# cpsw_CPSW3_08000000h register map
Vendor: Texas Instruments
Registers are 32-bit, read-write, reset 0x0 unless marked. A register's access mark holds for its fields unless they carry their own. Offsets are as the file gives them; [hi:lo] are bit positions; {n}, {i} and the like mark numbered series; 'fields as' and 'values as' point back to an identical list.

## cpsw3 (part 2 of 3)
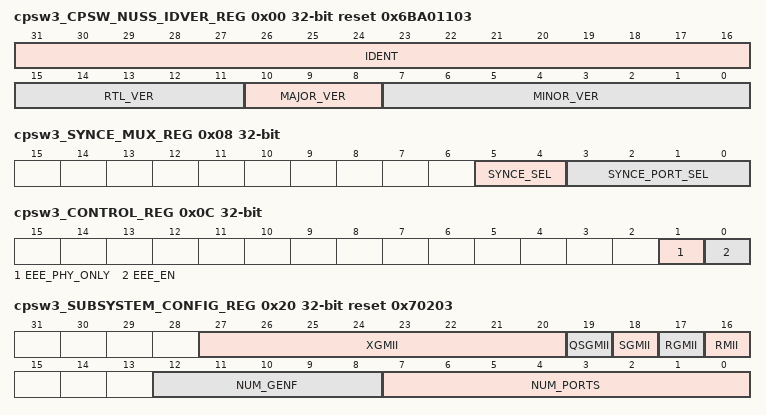
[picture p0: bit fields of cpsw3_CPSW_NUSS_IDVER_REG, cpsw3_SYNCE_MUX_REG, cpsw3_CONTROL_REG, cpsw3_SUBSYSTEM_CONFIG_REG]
0x00 cpsw3_CPSW_NUSS_IDVER_REG ro reset 0x6BA01103 — ID Version Register
  [31:16] IDENT — Identification value
  [15:11] RTL_VER — RTL version value
  [10:8] MAJOR_VER — Major version value
  [7:0] MINOR_VER — Minor version value
0x04 cpsw3_SYNCE_COUNT_REG — SyncE Count Register
  [31:0] SYNCE_CNT — Sync E Count Value
0x08 cpsw3_SYNCE_MUX_REG — SyncE Mux Register
  [5:4] SYNCE_SEL — Sync E Interface Select. 0h GMIIn_MRCLK_I input clock from selected port.1h RMII_MHZ_50_CLK (same for all ports).2h RGMIIn_RXC_I input clock from selected port.3h SERDESn_RXCLK from selected port.
  [3:0] SYNCE_PORT_SEL — Sync E Port SelectThis field selects the port that will be used for Synchronous Ethernet receive clock. The port interface is selected with synce_sel. 0h Port 1.1h Port 2.2h-Fh Reserved.
0x0C cpsw3_CONTROL_REG — Control Register
  [1] EEE_PHY_ONLY — Energy Efficient Enable Phy Only Mode: 0h The low power indicate state includes gating off the CPPI_GCLK to the CPSW.1h The low power indicate state does not gate the clock to the CPSW.
  [0] EEE_EN — Energy Efficient Ethernet Enable: 0h EEE is disabled1h EEE is enabled
0x10 cpsw3_SGMII_NON_FIBER_MODE_REG reset 0x3 — SGMII NON FIBER Mode Register
  [1:0] SGMII_NON_FIBER_MODE — This register bit goes to the CPSGMII mode input only
0x14 cpsw3_SERDES_RESET_ISO_REG — SyncE Mux Register
  [1:0] SERDES_RESET_ISO — These bits control whether the SERDES ignores the hard reset for isolation or not
0x1C cpsw3_SUBSSYSTEM_STATUS_REG ro — Subsystem Status Register
  [0] EEE_CLKSTOP_ACK — Energy Efficient Ethernet clockstop acknowledge from CPSW
0x20 cpsw3_SUBSYSTEM_CONFIG_REG ro reset 0x70203 — Subsystem Configuration Register
  [27:20] XGMII — The Number of XGMII Ports included in the CPSW_NUSS
  [19] QSGMII — QSGMII is included in the CPSW_NUSS
  [18] SGMII — SGMII is included in the CPSW_NUSS
  [17] RGMII — RGMII is included in the CPSW_NUSS
  [16] RMII — RMII is included in the CPSW_NUSS
  [12:8] NUM_GENF — The number of CPTS GENF outputs
  [7:0] NUM_PORTS — The total number of ports including the host port 0
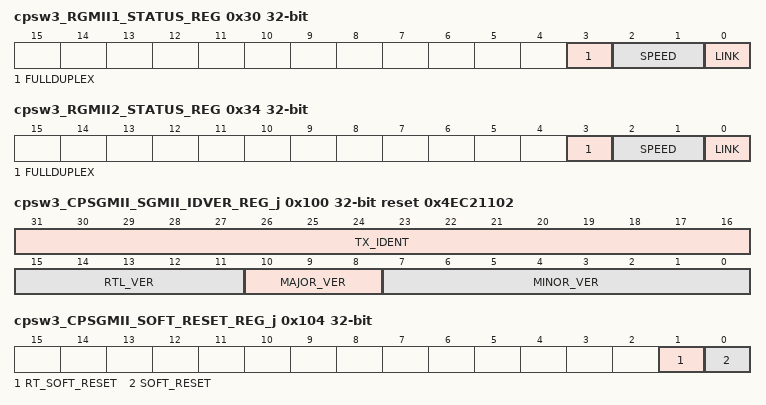
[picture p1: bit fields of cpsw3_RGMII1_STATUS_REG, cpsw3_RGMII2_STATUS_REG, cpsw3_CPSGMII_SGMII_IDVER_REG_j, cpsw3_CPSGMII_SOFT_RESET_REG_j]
0x30 cpsw3_RGMII1_STATUS_REG ro — RGMII1 Status Register
  [3] FULLDUPLEX — RGMII Port 1 full duplex: 0h Half-duplex1h Full-duplex
  [2:1] SPEED — RGMII Port 1 speed: 0h 10Mbps1h 100Mbps2h 1000Mbps3h Reserved
  [0] LINK — RGMII Port 1 link indicator: 0h Link is down,1h Link is up
0x34 cpsw3_RGMII2_STATUS_REG ro — RGMII2 Status Register
  [3] FULLDUPLEX — RGMII Port 2 full dulex: 0h Half-duplex1h Full-duplex
  [2:1] SPEED — RGMII Port 2 speed: 0h 10Mbps1h 100Mbps2h 1000Mbps3h Reserved
  [0] LINK — RGMII Port 2 link indicator: 0h Link is down1h Link is up
0x100 cpsw3_CPSGMII_SGMII_IDVER_REG_j ro reset 0x4EC21102 — SGMII IDVER register
  [31:16] TX_IDENT — MODULE value
  [15:11] RTL_VER — RTL version value
  [10:8] MAJOR_VER — Major version value
  [7:0] MINOR_VER — Minor version value
0x104 cpsw3_CPSGMII_SOFT_RESET_REG_j — SGMII Soft Reset Register
  [1] RT_SOFT_RESET — Transmit and receive software reset
  [0] SOFT_RESET — Software reset
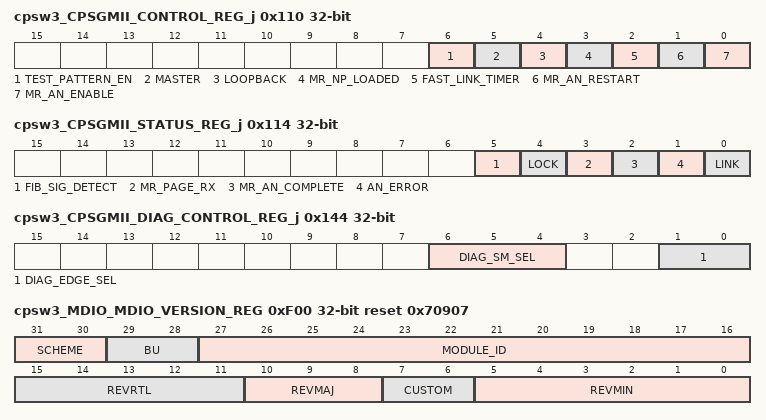
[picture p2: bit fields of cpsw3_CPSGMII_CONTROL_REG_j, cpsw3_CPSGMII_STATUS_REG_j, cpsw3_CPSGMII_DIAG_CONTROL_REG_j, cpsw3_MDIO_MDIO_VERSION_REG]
0x110 cpsw3_CPSGMII_CONTROL_REG_j — SGMII Control Register
  [6] TEST_PATTERN_EN — Test pattern enable
  [5] MASTER — Master mode
  [4] LOOPBACK — Loopback mode
  [3] MR_NP_LOADED — Next page loaded
  [2] FAST_LINK_TIMER
  [1] MR_AN_RESTART — Auto-negotiation restart
  [0] MR_AN_ENABLE — Auto-negotiation enable
0x114 cpsw3_CPSGMII_STATUS_REG_j ro — SGMII Status Register
  [5] FIB_SIG_DETECT — Fiber signal detect
  [4] LOCK
  [3] MR_PAGE_RX — Next page received
  [2] MR_AN_COMPLETE — Auto-negotiation complete
  [1] AN_ERROR — Auto-negotiation error
  [0] LINK — Link indicator
0x118 cpsw3_CPSGMII_MR_ADV_ABILITY_REG_j — SGMII MR Advertized Ability Register
  [15:0] MR_ADV_ABILITY — Advertised ability
0x11C cpsw3_CPSGMII_MR_NP_TX_REG_j — SGMII Next Pate Transmit Register
  [15:0] MR_NP_TX — Next page transmit
0x120 cpsw3_CPSGMII_MR_LP_ADV_ABILITY_REG_j ro — SGMII Link Partner Advertized Ability Register
  [15:0] MR_LP_ADV_ABILITY — Link partner advertised ability
0x124 cpsw3_CPSGMII_MR_LP_NP_RX_REG_j ro — SGMII Link Partner Next Page Receive Register
  [15:0] MR_LP_NP_RX — Link Partner Next Page Received
0x140 cpsw3_CPSGMII_DIAG_CLEAR_REG_j — SGMII Diagnostics Clear Register
  [0] DIAG_CLEAR — Diagnostics clear
0x144 cpsw3_CPSGMII_DIAG_CONTROL_REG_j — SGMII Diagnostics Control Register
  [6:4] DIAG_SM_SEL — Diagnostic select
  [1:0] DIAG_EDGE_SEL — Diagnostics hold signals edge select
0x148 cpsw3_CPSGMII_DIAG_STATUS_REG_j ro — SGMII Diagnostics Status Register
  [15:0] DIAG_STATUS — Diagnostics status
0xF00 cpsw3_MDIO access not given reset not defined
0xF00 cpsw3_MDIO_MDIO_VERSION_REG ro reset 0x70907 — MDIO Version Register
  [31:30] SCHEME
  [29:28] BU
  [27:16] MODULE_ID
  [15:11] REVRTL — RTL version
  [10:8] REVMAJ — Major version
  [7:6] CUSTOM — Custom version
  [5:0] REVMIN — Minor version
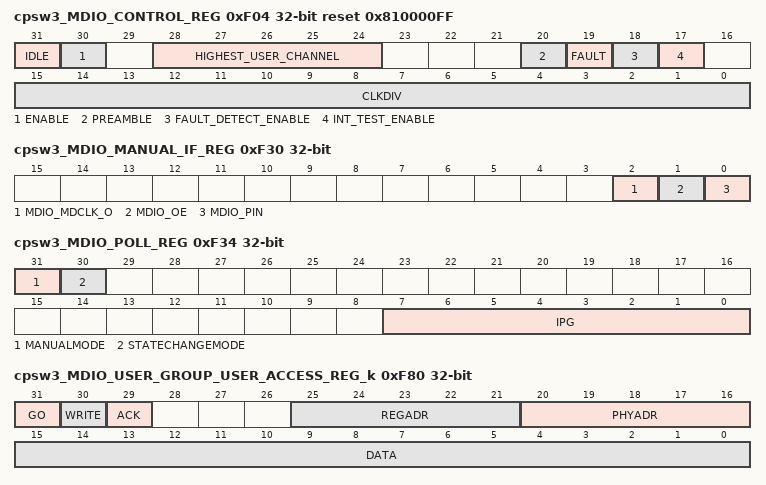
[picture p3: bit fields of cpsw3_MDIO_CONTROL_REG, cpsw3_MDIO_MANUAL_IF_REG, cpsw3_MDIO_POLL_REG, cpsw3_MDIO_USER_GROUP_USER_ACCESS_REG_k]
0xF04 cpsw3_MDIO_CONTROL_REG access per field reset 0x810000FF — MDIO Control Register
  [31] IDLE ro — MDIO state machine IDLE. Set to 1h when the state machine is in the idle state.
  [30] ENABLE rw — Enable control. Writing a 1h to this bit enables the MDIO state machine, writing a 0h disables it. If the MDIO state machine is active at the time it is disabled, it will complete the current operation before halting and setting the idle bit. If using byte access, the enable bit has to be the last bit written in this register.
  [28:24] HIGHEST_USER_CHANNEL ro — Highest user channel. This field specifies the highest useraccess channel that is available in the module and is currently set to 1h. This implies that MDIOUserAccess1 is the highest available user access channel.
  [20] PREAMBLE rw — Preamble disable. Writing a 1h to this bit disables this device from sending MDIO frame preambles in clause 22 mode of operation. This bit has no effect in clause 45 mode of operation.
  [19] FAULT rw — Fault indicator. This bit is set to 1h if the MDIO pins fail to read back what the device is driving onto them. This indicates a physical layer fault and the module state machine is reset. Writing a 1h to it clears this bit.
  [18] FAULT_DETECT_ENABLE rw — Fault detect enable. This bit has to be set to 1h to enable the physical layer fault detection.
  [17] INT_TEST_ENABLE rw — Interrupt test enable. This bit can be set to 1h to enable the host to set the userint and linkint bits for test purposes.
  [15:0] CLKDIV rw — Clock Divider. This field specifies the division ratio between CLK and the frequency of MDCLK. When clkdiv is set to 0h, MDCLK is disabled and output is driven to a high logic state. MDCLK frequency = clk frequency/(clkdiv+1).
0xF08 cpsw3_MDIO_ALIVE_REG — MDIO Alive Register
  [31:0] ALIVE — MDIO Alive. Each of the 32-bits of this register is set if the most recent access to the PHY with address corresponding to the register bit number was acknowledged by the PHY, the bit is reset if the PHY fails to acknowledge the access. Both the user and polling accesses to a PHY will cause the corresponding alive bit to be updated. The alive bits are intended to be used to give an indication of the presence or not of the PHY with the corresponding address. Writing a 1h to any bit will clear it, writing a 0h has no effect.
0xF0C cpsw3_MDIO_LINK_REG ro — MDIO Link Register
  [31:0] LINK — MDIO Link state. This register is updated after a read of the Generic Status Register of a PHY. The corresponding bit is set if the PHY with the corresponding address has link and the PHY acknowledges the read transaction. The bit is cleared to 0h if the PHY indicates it does not have link or fails to acknowledge the read transaction. Writes to the register have no effect. In addition, in Normal Mode Operation, the status of the two PHYs specified in the MDIOUserPhySel registers can be determined using the MLINK input pins. This is determined by the linksel bit in the MDIOUserPhySel register. In State Change Mode the MLINK input pins are unused.
0xF10 cpsw3_MDIO_LINK_INT_RAW_REG — MDIO Link Interrupt Raw Register
  [1:0] LINKINTRAW — MDIO link change event raw value. Normal mode operation: When asserted '1', a bit indicates that there was an MDIO link change event (i.e. change in the MDIOLink register) corresponding to the PHY address in the MDIOUserPhySel register. [0]LINKINTRAW and [1]LINKINTRAW correspond to MDIOUserPhySel0 and MDIOUserPhysel1, respectively. Writing a 1h will clear the event and writing 0h has no effect. If the [17] INT_TEST_ENABLE bit in the CPSW_MDIO_CONTROL_REG register is set, the host may set LINKINTRAW bits to a 1h which may be used for test purposes. MDIO link change event raw value. State Change Mode operation: The [0]LINKINTRAW bit will be asserted '1' when any bit (for any PHY) in the MDIOAlive or MDIOLink registers changes due to MDIO operations. The [1]LINKINTRAW bit is unused in State Change Mode. State Change Mode allows any state change in any PHY to issue an interrupt. If the [17] INT_TEST_ENABLE bit in the CPSW_MDIO_CONTROL_REG register is set, the host may set the [0]LINKINTRAW bit to a 1h which may be used for test purposes.
0xF14 cpsw3_MDIO_LINK_INT_MASKED_REG — MDIO Link Interrupt Masked Register
  [1:0] LINKINTMASKED — MDIO link change interrupt masked value. Normal mode operation: When asserted '1', a bit indicates that there was an MDIO link change event (i.e. change in the MDIOLink register) corresponding to the PHY address in the MDIOUserPhySel register and the corresponding CPSW_MDIO_USER_PHY_SEL_REG_k[6] LINKINT_ENABLE bit was set. CPSW_MDIO_LINK_INT_MASKED_REG[0] LINKINTMASKED and [1] LINKINTMASKED correspond to MDIOUserPhySel0 and MDIOUserPhysel1, respectively. Writing a 1h will clear the interrupt and writing 0h has no effect. These masked interrupt bits are the MDIO_LINKINT[1:0] pin values. MDIO link change interrupt masked value. State Change Mode operation: The [0] LINKINTMASKED bit will be asserted '1' when CPSW_MDIO_LINK_INT_RAW_REG[0] LINKINTRAW is asserted '1' and when the CPSW_MDIO_LINK_INT_MASK_SET_REG[0] LINKINTMASKSET bit is set to 1h. Writing a 1h will clear [0] LINKINTMASKED (and the MDIO_LINKINT[0] output) and writing 0h has no effect. The [1] LINKINTMASKED bit is not used in State Change Mode (MDIO_LINKINT[1] is therefore also unused in State Change Mode).
0xF18 cpsw3_MDIO_LINK_INT_MASK_SET_REG — MDIO Link Interrupt Mask Set Register
  [0] LINKINTMASKSET — MDIO link interrupt mask set. Normal Mode Operation: This register is not used in normal mode. In normal mode the MDIO_LINKINT[1:0] interrupts are enabled with the linkint_enable bit in the associated MDIOUserPhySel0/1 register. MDIO link interrupt mask set. State Change Mode Operation: Writing this bit to 1h will enable the MDIO link status change interrupt (MDIO_LINKINT[0]) to be asserted when [0] LINKINTRAW is asserted.
0xF1C cpsw3_MDIO_LINK_INT_MASK_CLEAR_REG — MDIO Link Interrupt Mask Clear Register
  [0] LINKINTMASKCLR — MDIO link interrupt mask clear. Normal Mode Operation: This register is not used in normal mode. In normal mode the MDIO_LINKINT[1:0] interrupts are enabled with the linkint_enable bit in the associated MDIOUserPhySel0/1 register. MDIO link interrupt mask clear. State Change Mode Operation: Writing this bit to 1h will disable the MDIO link status change interrupt (MDIO_LINKINT[0]) regardless of the [0] LINKINTRAW bit value.
0xF20 cpsw3_MDIO_USER_INT_RAW_REG — MDIO User Interrupt Raw Register
  [1:0] USERINTRAW — Raw value of MDIO user command complete event for MDIOUserAccess1 through MDIOUserAccess0, respectively. When asserted '1', a bit indicates that the previously scheduled PHY read or write command using that particular MDIOUserAccess register has completed. Writing a 1h will clear the event and writing 0h has no effect. If the [17] INT_TEST_ENABLE bit in the CPSW_MDIO_CONTROL_REG register is set, the host may set the userintraw bits to a 1h. This mode may be used for test purposes.
0xF24 cpsw3_MDIO_USER_INT_MASKED_REG — MDIO User Interrupt Masked Register
  [1:0] USERINTMASKED — Masked value of MDIO user command complete interrupt for MDIOUserAccess1 through MDIOUserAccess0, respectively. When asserted '1', a bit indicates that the previously scheduled PHY read or write command using that particular MDIOUserAccess register has completed and the corresponding userintmaskset bit is set to 1h. Writing a 1h will clear the interrupt and writing 0h has no effect. If the [17] INT_TEST_ENABLE bit in the CPSW_MDIO_CONTROL_REG register is set, the host may set the CPSW_MDIO_USER_INT_MASKED_REG[1-0] USERINTMASKED bits to a 1h. This mode may be used for test purposes.
0xF28 cpsw3_MDIO_USER_INT_MASK_SET_REG — MDIO User Interrupt Mask Set Register
  [1:0] USERINTMASKSET — MDIO user interrupt mask set for CPSW_MDIO_USER_INT_MASKED_REG[1-0] USERINTMASKED, respectively. Writing a bit to 1h will enable MDIO user command complete interrupts for that particular MDIOUserAccess register. MDIO user interrupt for a particular MDIOUserAccess register is disabled if the corresponding bit is 0h. Writing a 0h to this register has no effect.
0xF2C cpsw3_MDIO_USER_INT_MASK_CLEAR_REG — MDIO User Interrupt Mask Clear Register
  [1:0] USERINTMASKCLR — MDIO user command complete interrupt mask clear for CPSW_MDIO_USER_INT_MASKED_REG[1-0] USERINTMASKED, respectively. Writing a bit to 1h will disable further user command complete interrupts for that particular MDIOUserAccess register. Writing a 0h to this register has no effect.
0xF30 cpsw3_MDIO_MANUAL_IF_REG — MDIO Manual Interface Register
  [2] MDIO_MDCLK_O — MDIO Clock Output. This value is the MDCLK_O output value when the [31] MANUALMODE bit is set in the CPSW_MDIO_POLL_REG register.
  [1] MDIO_OE — MDIO Output Enable. This value is inverted and output on the MDIO_OE_N output when the [31] MANUALMODE bit is set in the CPSW_MDIO_POLL_REG register.
  [0] MDIO_PIN — MDIO Pin Value. This is the external MDIO data pin value when the [31] MANUALMODE bit is set in the CPSW_MDIO_POLL_REG register. That is, this value is driven on the MDIO_O (the MDIO serial data output) when MDIO_OE is asserted '1'. The read value for this bit comes from MDIO_I (the MDIO serial data input). If MDIO_OE is asserted '1' and MDIO_PIN is written with a 1h then MDIO_PIN should read a 1h if there are no external devices pulling the MDIO data line low.
0xF34 cpsw3_MDIO_POLL_REG — MDIO Poll Register
  [31] MANUALMODE — MDIO Manual Mode. When set 1h, the MDIO pins are directly controlled by software through the bits in the CPSW_MDIO_MANUAL_IF_REG register 1h Manual Mode.
  [30] STATECHANGEMODE — MDIO State Change Mode. When set, the MDIO is operating in State Change Mode. When clear, the MDIO is operating in normal mode. State change mode effects interrupt operations. 0h Normal Mode.1h State Change Mode.
  [7:0] IPG — Polling Inter Packet Gap Value. This value is the number of MDCLK_O clocks between each poll when polling is enabled.
0xF38 cpsw3_MDIO_POLL_EN_REG reset 0xFFFFFFFF — MDIO Poll Enable Register
  [31:0] POLL_EN — MDIO Poll Enable. When set, the bit indicates that the associated PHY will be included in polling operations. When clear, the associated PHY will not be polled. Each bit in this field is associated with a PHY. Bit zero is associated with PHY 0 and so on. Due to a limitation in the hardware, bit 31 must always be set (regardless of the value of the preamble disable bit ([20] PREAMBLE) in the CPSW_MDIO_CONTROL_REG register. However, there does not have to be a PHY at address 31.
0xF3C cpsw3_MDIO_CLAUS45_REG — MDIO Clause45 Register
  [31:0] CLAUSE45 — MDIO clause 45 mode. When a clause45 bit is cleared 0h, the PHY associated with the clause45 bit is operating in the clause 22 mode. When set 1h, the PHY associated with the clause45 bit is operating in the clause 45 mode. Bit 0 is associated with PHY 0 and so on.
0xF40 cpsw3_MDIO_USER_ADDR0_REG — MDIO Address 0 Register
  [15:0] USER_ADDR0 — MDIO User Address 0. In clause 45 mode, this field value is the address transferred in the address transfer inititated before each MDIOUserAccess0 access. This is not used for PHY's operating in clause22 mode as there is no address transfer preceeding each MDIOUserAccess0 access.
0xF44 cpsw3_MDIO_USER_ADDR1_REG — MDIO Address 1 Register
  [15:0] USER_ADDR1 — MDIO User Address 1. In clause 45 mode, this field value is the address transferred in the address transfer inititated before each MDIOUserAccess1 access. This is not used for PHY's operating in clause22 mode as there is no address transfer preceeding each MDIOUserAccess1 access.
0xF80 cpsw3_MDIO_USER_GROUP_USER_ACCESS_REG_k — MDIO User Access Register
  [31] GO — Go. Writing a 1h to this bit causes the MDIO state machine to perform an MDIO access when it is convenient for it to do so, this is not an instantaneous process. Writing a 0h to this bit has no effect. This bit is write able only if the MDIO state machine is enabled. This bit will self clear when the requested access has been completed. Any writes to the MDIOUserAccess0 register are blocked when the go bit is 1h. If byte access is being used, the go bit should be written last.
  [30] WRITE — Write enable. Setting this bit to a 1h causes the MDIO transaction to be a register write, otherwise it is a register read.
  [29] ACK — Acknowledge. This bit is set if the PHY acknowledged the read transaction.
  [25:21] REGADR — Register address. This field specifies the PHY register to be accessed for this transaction in clause 22 mode or the MMD value in clause 45 mode.
  [20:16] PHYADR — PHY address. This field specifies the PHY to be accessed for this transaction.
  [15:0] DATA — User data. The data value read from or to be written to the specified PHY register.
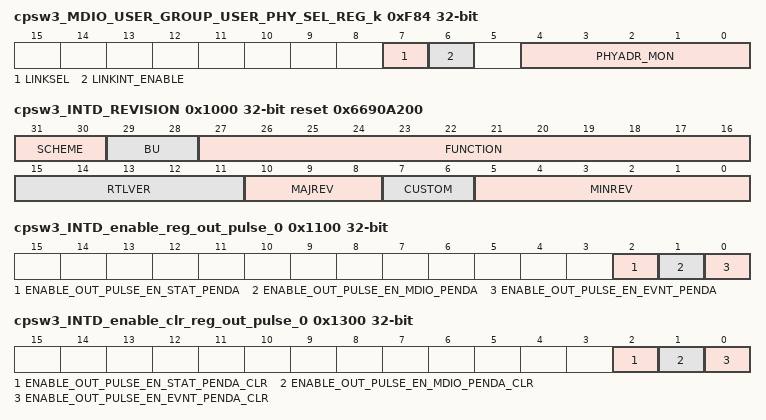
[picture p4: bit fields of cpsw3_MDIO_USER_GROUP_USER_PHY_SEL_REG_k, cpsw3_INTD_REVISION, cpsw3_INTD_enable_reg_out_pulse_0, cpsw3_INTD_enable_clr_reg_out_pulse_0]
0xF84 cpsw3_MDIO_USER_GROUP_USER_PHY_SEL_REG_k — MDIO User PHY Select Register
  [7] LINKSEL — Link status determination select. Set to 1h to determine link status using the MLINK pin. Default value is 0h which implies that the link status is determined by the MDIO state machine.
  [6] LINKINT_ENABLE — Link change interrupt enable. Set to 1h to enable link change status interrupts for PHY address specified in [4-0] PHYADR_MON. Link change interrupts are disabled if this bit is set to 0h.
  [4:0] PHYADR_MON — PHY address whose link status is monitored.
0x1000 cpsw3_INTD access not given reset not defined
0x1000 cpsw3_INTD_REVISION ro reset 0x6690A200 — Revision Register
  [31:30] SCHEME
  [29:28] BU
  [27:16] FUNCTION — Module ID
  [15:11] RTLVER — RTL revisions
  [10:8] MAJREV — Major revision
  [7:6] CUSTOM — Custom revision
  [5:0] MINREV — Minor revision
0x1010 cpsw3_INTD_eoi_reg — End of Interrupt Register
  [7:0] EOI_VECTOR — End of Interrupt Vector
0x1014 cpsw3_INTD_intr_vector_reg ro — Interrupt Vector Register
  [31:0] INTR_VECTOR
0x1100 cpsw3_INTD_enable_reg_out_pulse_0 access not given — Enable Register 0
  [2] ENABLE_OUT_PULSE_EN_STAT_PENDA — Enable Set for out_pulse_en_stat_penda (access R/W1TS)
  [1] ENABLE_OUT_PULSE_EN_MDIO_PENDA — Enable Set for out_pulse_en_mdio_penda (access R/W1TS)
  [0] ENABLE_OUT_PULSE_EN_EVNT_PENDA — Enable Set for out_pulse_en_evnt_penda (access R/W1TS)
0x1300 cpsw3_INTD_enable_clr_reg_out_pulse_0 access not given — Enable Clear Register 0
  [2] ENABLE_OUT_PULSE_EN_STAT_PENDA_CLR — Enable Clear for out_pulse_en_stat_penda (access R/W1TC)
  [1] ENABLE_OUT_PULSE_EN_MDIO_PENDA_CLR — Enable Clear for out_pulse_en_mdio_penda (access R/W1TC)
  [0] ENABLE_OUT_PULSE_EN_EVNT_PENDA_CLR — Enable Clear for out_pulse_en_evnt_penda (access R/W1TC)
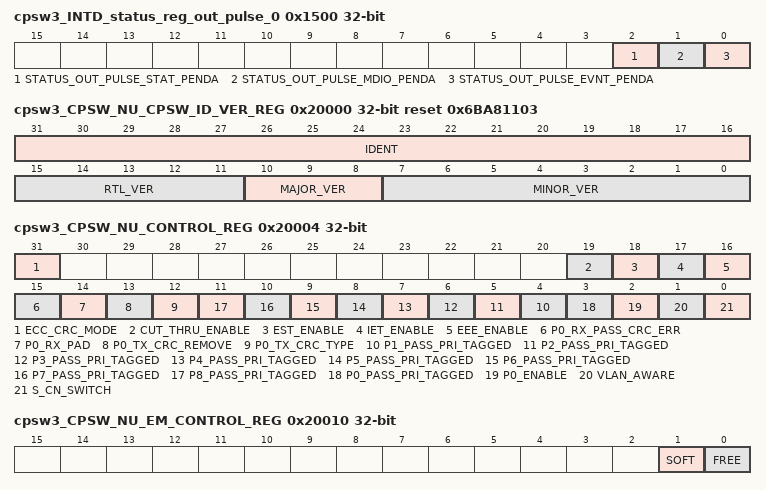
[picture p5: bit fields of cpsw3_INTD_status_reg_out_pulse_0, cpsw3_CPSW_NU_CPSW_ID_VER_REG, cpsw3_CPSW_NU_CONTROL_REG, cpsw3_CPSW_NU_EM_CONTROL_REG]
0x1500 cpsw3_INTD_status_reg_out_pulse_0 ro — Status Register 0
  [2] STATUS_OUT_PULSE_STAT_PENDA — Status for out_pulse_en_stat_penda
  [1] STATUS_OUT_PULSE_MDIO_PENDA — Status for out_pulse_en_mdio_penda
  [0] STATUS_OUT_PULSE_EVNT_PENDA — Status for out_pulse_en_evnt_penda
0x1A80 cpsw3_INTD_intr_vector_reg_out_pulse ro — Interrupt Vector for out_pulse
  [31:0] INTR_VECTOR_OUT_PULSE — Interrupt Vector
0x20000 cpsw3_CPSW_NU access not given reset not defined
0x20000 cpsw3_CPSW_NU_CPSW_ID_VER_REG ro reset 0x6BA81103 — CPSW ID Version
  [31:16] IDENT — Identification Value
  [15:11] RTL_VER — RTL Version Value
  [10:8] MAJOR_VER — Major Version Value
  [7:0] MINOR_VER — Minor Version Value
0x20004 cpsw3_CPSW_NU_CONTROL_REG — CPSW Switch Control
  [31] ECC_CRC_MODE — ECC CRC Mode. 0h ECC errors induced through the ECC aggregator flip bits in the packet headers (not in packet data).1h ECC errors induced through the ECC aggregator flip bits in the packet data (not in the packet headers).
  [19] CUT_THRU_ENABLE — Cut Thru Enable. 0h Cut Thru disabled1h Cut Thru enabled
  [18] EST_ENABLE — Enhanced Scheduled Traffic enable (EST) 0h EST is disabled1h EST is enabled
  [17] IET_ENABLE — Intersperced Express Traffic enable (IET) 0h IET is disabled1h IET is enabled
  [16] EEE_ENABLE — Energy Efficient Ethernet enable 0h Energy Efficient Ethernet is disabled1h Energy Efficient Ethernet is enabled
  [15] P0_RX_PASS_CRC_ERR — Port 0 Pass Received CRC errors 0h Packets received with CRC errors on Port 0 are dropped.1h Packets received with CRC errors on Port 0 are transferred to the destination ports.
  [14] P0_RX_PAD — Port 0 Receive Short Packet Pad 0h Short packets are dropped.1h Short packets are padded to 64-bytes (with pad and added CRC) if the CRC is not passed in. Short packets are dropped if the CRC is passed (in the Info0 word).
  [13] P0_TX_CRC_REMOVE — Port 0 Transmit CRC remove. 0h Do not remove the CRC on Port 0 transmit (egress) packets.1h Remove the CRC on all Port 0 transmit (egress) packets.
  [12] P0_TX_CRC_TYPE
  [n+3] P{n}_PASS_PRI_TAGGED (n=1..8) — Port {n} Pass Priority Tagged 0h Priority tagged packets have the zero VID replaced with the input port Enet_P{n}_PORT_VLAN[11:0] on ingress.1h Priority tagged packets are processed unchanged.
  [3] P0_PASS_PRI_TAGGED — Port 0 Pass Priority Tagged 0h Priority tagged packets have the zero VID replaced with the input port P0_PORT_VLAN[11:0] on ingress.1h Priority tagged packets are processed unchanged.
  [2] P0_ENABLE — Port 0 Enable 0h CPPI port (port 0) packet operations are disabled1h CPPI port (port 0) packet operations are enabled
  [1] VLAN_AWARE — VLAN Aware Mode: 0h CPSW_NU is in the VLAN unaware mode.1h CPSW_NU is in the VLAN aware mode.
  [0] S_CN_SWITCH — Service or Customer VLAN switch. 0h Customer switch. VLAN processing uses the inner_vlan_ltype.1h Servide switch. VLAN processing uses the outer_vlan_ltype.
0x20010 cpsw3_CPSW_NU_EM_CONTROL_REG — CPSW Emulation Control
  [1] SOFT — Emulation Soft Bit
  [0] FREE — Emulation Free Bit
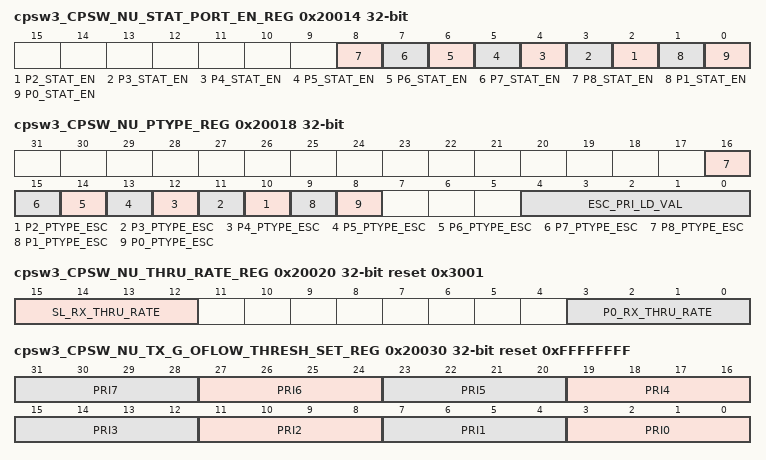
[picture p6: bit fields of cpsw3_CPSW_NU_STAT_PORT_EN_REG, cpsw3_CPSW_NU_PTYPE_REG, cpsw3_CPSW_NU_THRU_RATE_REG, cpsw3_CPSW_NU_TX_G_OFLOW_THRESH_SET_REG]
0x20014 cpsw3_CPSW_NU_STAT_PORT_EN_REG — CPSW Statistics Port Enable
  [n] P{n}_STAT_EN (n=2..8) — Port {n} Statistics Enable (if N > {n}) 0h Port {n} statistics are not enabled1h Port {n} statistics are enabled.
  [1] P1_STAT_EN — Port 1 Statistics Enable 0h Port 1 statistics are not enabled1h Port 1 statistics are enabled.
  [0] P0_STAT_EN — Port 0 Statistics Enable 0h Port 0 statistics are not enabled1h Port 0 statistics are enabled.
0x20018 cpsw3_CPSW_NU_PTYPE_REG — CPSW Transmit Priority Type
  [n+8] P{n}_PTYPE_ESC (n=2..8) — Port {n} Priority Type Escalate (if N > {n}) 0h Port {n} priority type fixed1h Port {n} priority type escalate
  [9] P1_PTYPE_ESC — Port 1 Priority Type Escalate 0h Port 1 priority type fixed1h Port 1 priority type escalate
  [8] P0_PTYPE_ESC — Port 0 Priority Type Escalate 0h Port 0 priority type fixed1h Port 0 priority type escalate
  [4:0] ESC_PRI_LD_VAL — Escalate Priority Load Value. When a port is in escalate priority, this is the number of higher priority packets sent before the next lower priority is allowed to send a packet. Escalate priority allows lower priority packets to be sent at a fixed rate relative to the next higher priority. The min value of ESC_PRI_LD_VAL = 2h.
0x2001C cpsw3_CPSW_NU_SOFT_IDLE_REG — CPSW Software Idle
  [0] SOFT_IDLE — Software Idle. 0h Not in Idle.1h Command a MCU_CPSW0 software Idle. When set, no packets will be started to be unloaded from ports 0 through 4 receive unload. Packets that are currently being unloaded are unaffected.
0x20020 cpsw3_CPSW_NU_THRU_RATE_REG reset 0x3001 — CPSW Thru Rate
  [15:12] SL_RX_THRU_RATE — Ethernet Port Switch FIFO receive through rate. This register value is the maximum throughput of the Ethernet ports to the crossbar SCR. The default is one 8-byte word for every 3 VBUSP_GCLK periods maximum. The minimum value is 2. This is not a field that is intended to be changed by a user.
  [3:0] P0_RX_THRU_RATE — CPPI FIFO (port 0) receive through rate. This register value is the maximum throughput of the CPPI FIFO (port 0) into the MCU_CPSW0. The minimum value is 1. This field is not intended to be changed by the user.
0x20024 cpsw3_CPSW_NU_GAP_THRESH_REG reset 0xB — CPSW Transmit FIFO Short Gap Threshold
  [4:0] GAP_THRESH — Ethernet Port Short Gap Threshold. This is the Ethernet port associated FIFO transmit block usage value for triggering transmit short gap (when short gap is enabled).
0x2002C cpsw3_CPSW_NU_EEE_PRESCALE_REG — CPSW Energy Efficient Ethernet Prescale Value
  [11:0] EEE_PRESCALE — Energy Efficient Ethernet Pre-scale count load value
0x20030 cpsw3_CPSW_NU_TX_G_OFLOW_THRESH_SET_REG reset 0xFFFFFFFF — CPSW PFC Tx Global Out Flow Threshold Set
  [4n+3:4n] PRI{n} (n=0..7) — Priority Based Flow Control Global Outflow Usage Threshold for Pri {n}
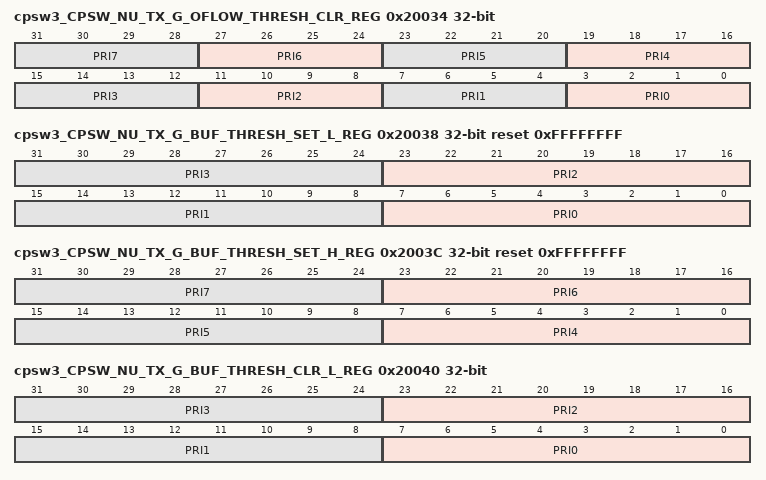
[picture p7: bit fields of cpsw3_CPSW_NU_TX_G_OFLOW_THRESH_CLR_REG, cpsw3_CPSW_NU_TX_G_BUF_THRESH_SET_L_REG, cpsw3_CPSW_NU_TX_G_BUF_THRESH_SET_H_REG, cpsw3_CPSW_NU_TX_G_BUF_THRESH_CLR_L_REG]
0x20034 cpsw3_CPSW_NU_TX_G_OFLOW_THRESH_CLR_REG — CPSW PFC Tx Global Out Flow Threshold Clear
  fields as cpsw3_CPSW_NU_TX_G_OFLOW_THRESH_SET_REG
0x20038 cpsw3_CPSW_NU_TX_G_BUF_THRESH_SET_L_REG reset 0xFFFFFFFF — CPSW PFC Global Tx Buffer Threshold Set Low
  [8n+7:8n] PRI{n} (n=0..3) — Priority Based Flow Control Global Buffer Usage Threshold for Priority {n}
0x2003C cpsw3_CPSW_NU_TX_G_BUF_THRESH_SET_H_REG reset 0xFFFFFFFF — CPSW PFC Global Tx Buffer Threshold Set High
  [8n-25:8n-32] PRI{n} (n=4..7) — Priority Based Flow Control Global Buffer Usage Threshold for Priority {n}
0x20040 cpsw3_CPSW_NU_TX_G_BUF_THRESH_CLR_L_REG — CPSW PFC Global Tx Buffer Threshold Clear Low
  fields as cpsw3_CPSW_NU_TX_G_BUF_THRESH_SET_L_REG
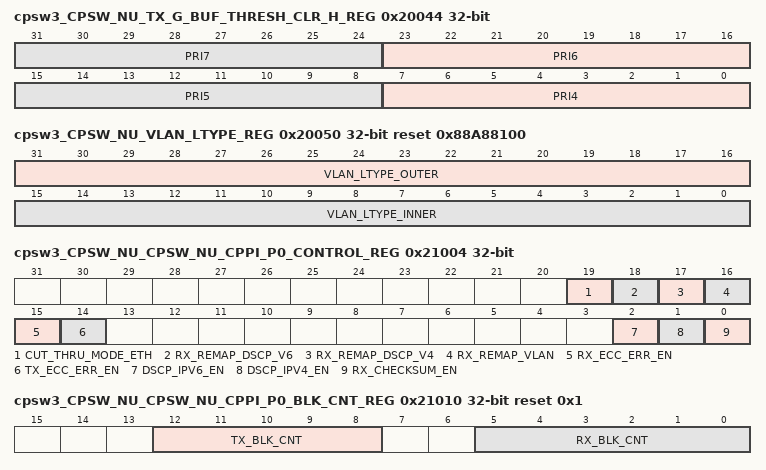
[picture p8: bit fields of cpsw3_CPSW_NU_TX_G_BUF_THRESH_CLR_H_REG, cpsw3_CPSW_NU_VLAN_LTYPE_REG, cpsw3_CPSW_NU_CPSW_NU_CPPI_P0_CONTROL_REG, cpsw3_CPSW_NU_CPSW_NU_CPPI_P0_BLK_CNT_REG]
0x20044 cpsw3_CPSW_NU_TX_G_BUF_THRESH_CLR_H_REG — CPSW PFC Global Tx Buffer Threshold Clear High
  fields as cpsw3_CPSW_NU_TX_G_BUF_THRESH_SET_H_REG
0x20050 cpsw3_CPSW_NU_VLAN_LTYPE_REG reset 0x88A88100 — VLAN Length/type
  [31:16] VLAN_LTYPE_OUTER — Outer VLAN LType
  [15:0] VLAN_LTYPE_INNER — Inner VLAN LType
0x20054 cpsw3_CPSW_NU_EST_TS_DOMAIN_REG — Enhanced Scheduled Traffic Host Event Domain
  [7:0] EST_TS_DOMAIN — Enhanced Scheduled Traffic Host Event Domain. This value is used as the domain in the CPTS event to indicate that the event came from EST.
0x20058 cpsw3_CPSW_NU_CUT_THRESHOLD_REG — Cut-thru Threshold
  [3:0] CUT_THRESH — Cut_thru_threshold. This is not intended to be changed by software.
0x2005C cpsw3_CPSW_NU_FREQUENCY_REG — CPSW CPPI_CLK Frequency in Mhz
  [9:0] CPSW_FREQUENCY
0x20060 cpsw3_CPSW_NU_IET_HOLD_CNT_LD_VAL_REG reset 0x64 — IET Hold Count Load Value for cut thru packets
  [7:0] IET_HOLD_CNT_LD_VAL — Cut-thru IET Hold Count Load Value. This value is loaded into counters to count the time that cut-thru packets are allowed to prempt traffic in advance in order to reduce cut-thru latency with IET operations. This is not intended to be changed by software.
0x20100 cpsw3_CPSW_NU_TX_PRI0_MAXLEN_REG reset 0x7E8 — Transmit Priority 0 Maximum Length
  [13:0] TX_PRI0_MAXLEN — Transmit Priority 0 Maximum Packet Length. This value determines the maximum packet length that will be transmitted on egress for all ports. The packet length compared to the maximum length value is the ingress packet length (not the actual egress packet length which is the length before VLAN addition or removal). Packets on a priority that are larger than the CPSW_TX_PRI0_MAXLEN_REG to CPSW_TX_PRI7_MAXLEN_REG value are dropped. The reset value is decimal 2024 when fifo_blk_size=1 and 9604 when fifo_blk_size=4.
{0x20100+4i} cpsw3_CPSW_NU_TX_PRI{i}_MAXLEN_REG reset 0x7E8 (i=1..7) — Transmit Priority {i} Maximum Length
  [13:0] TX_PRI{i}_MAXLEN — Transmit Priority {i} Maximum Packet Length. This value determines the maximum packet length that will be transmitted on Ethernet egress for all Ethernet ports. The packet length compared to the maximum length value is the ingress packet length (not the actual egress packet length which is the length before VLAN addition or removal). Packets on a priority that are larger than the CPSW_TX_PRI0_MAXLEN_REG to CPSW_TX_PRI7_MAXLEN_REG value are dropped. The reset value is decimal 2024 when fifo_blk_size=1 and 9604 when fifo_blk_size=4.
0x21000 cpsw3_CPSW_NU_CPSW_NU_CPPI access not given reset not defined
0x21004 cpsw3_CPSW_NU_CPSW_NU_CPPI_P0_CONTROL_REG — CPPI Port 0 Control
  [19] CUT_THRU_MODE_ETH — Port 0 Cut-Thru Mode. Packets always egress from the host port (CPPI egress) store-and- forward regardless of this bit setting. This bit determines how a receive port operates when the host port is in a cut-thru packet destination mask. 0h Force packets with the host port in the destination mask to be store-and-forward to all destination ports.1h The host port operates similar to Ethernet ports. A cut-thru packet with the host in the destination mask will not force the packet to be store-and-forward unless the cut-thru packet is held off due to word counts or because another cut-thru packet on the host port priority.
  [18] RX_REMAP_DSCP_V6 — Port 0 receive remap thread to DSCP IPV6 priority.
  [17] RX_REMAP_DSCP_V4 — Port 0 receive remap thread to DSCP IPV6 priority.
  [16] RX_REMAP_VLAN — Port 0 receive remap thread to VLAN.
  [15] RX_ECC_ERR_EN — Port 0 receive ECC Error Enable. This bit must be set to enable receive ECC error operations
  [14] TX_ECC_ERR_EN — Port 0 transmit ECC Error Enable. This bit must be set to enable transmit ECC error operations
  [2] DSCP_IPV6_EN — Port 0 IPv6 DSCP enable 0h IPV6 DSCP priority mapping is disabled1h IPV6 DSCP priority mapping is enabled
  [1] DSCP_IPV4_EN — Port 0 IPV4 DSCP enable 0h IPV4 DSCP priority mapping is disabled1h IPV4 DSCP priority mapping is enabled
  [0] RX_CHECKSUM_EN — Port 0 Receive (port 0 ingress) Checksum Enable 0h Port 0 receive checksum is disabled1h Port 0 receive checksum is enabled
0x21008 cpsw3_CPSW_NU_CPSW_NU_CPPI_P0_FLOW_ID_OFFSET_REG — CPPI Port 0 Flow ID Offset
  [13:0] VALUE — This value is added to the thread/Flow_ID in CPPI transmit PSI Info Word 0
0x21010 cpsw3_CPSW_NU_CPSW_NU_CPPI_P0_BLK_CNT_REG ro reset 0x1 — CPPI Port 0 FIFO Block Usage Count
  [12:8] TX_BLK_CNT — Port 0 Transmit Block Count Usage. This value is the number of blocks allocated to the FIFO logical transmit queues.
  [5:0] RX_BLK_CNT — Port 0 Receive Block Count Usage. This value is the number of blocks allocated in the receive FIFO.
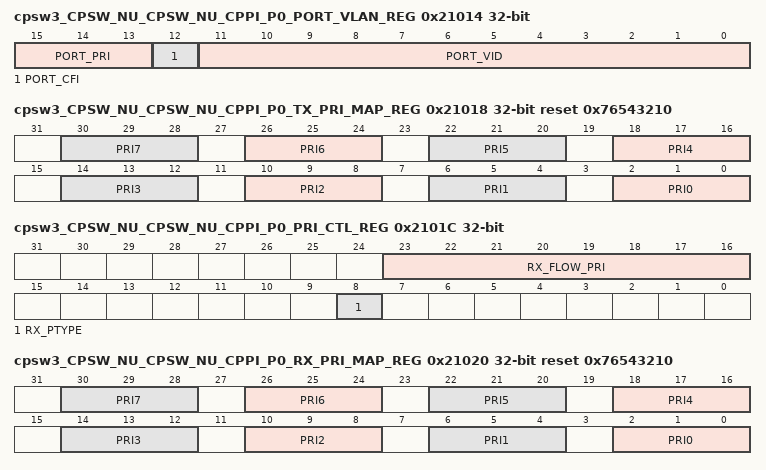
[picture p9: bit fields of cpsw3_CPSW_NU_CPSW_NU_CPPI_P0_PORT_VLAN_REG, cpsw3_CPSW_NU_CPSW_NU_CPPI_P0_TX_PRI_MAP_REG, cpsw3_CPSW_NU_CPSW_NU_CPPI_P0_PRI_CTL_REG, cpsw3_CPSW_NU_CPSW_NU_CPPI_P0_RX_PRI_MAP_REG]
0x21014 cpsw3_CPSW_NU_CPSW_NU_CPPI_P0_PORT_VLAN_REG — CPPI Port 0 VLAN
  [15:13] PORT_PRI — Port VLAN Priority
  [12] PORT_CFI — Port CFI bit
  [11:0] PORT_VID — Port VLAN ID
0x21018 cpsw3_CPSW_NU_CPSW_NU_CPPI_P0_TX_PRI_MAP_REG reset 0x76543210 — CPPI Port 0 Tx Header Pri to Switch Pri Mapping
  [4n+2:4n] PRI{n} (n=0..7) — Priority {n}. A packet header priority of {n}h is given this switch queue pri.
0x2101C cpsw3_CPSW_NU_CPSW_NU_CPPI_P0_PRI_CTL_REG — CPPI Port 0 Priority Control
  [23:16] RX_FLOW_PRI — Receive Priority Based Flow Control Enable (per priority).
  [8] RX_PTYPE — Receive Priority Type 0h Fixed priority1h Round Robin priority
0x21020 cpsw3_CPSW_NU_CPSW_NU_CPPI_P0_RX_PRI_MAP_REG reset 0x76543210 — CPPI Port 0 RX Pkt Pri to Header Pri Map
  [4n+2:4n] PRI{n} (n=0..7) — Priority {n}. A packet pri of {n}h is mapped (changed) to this header packet pri.
0x21024 cpsw3_CPSW_NU_CPSW_NU_CPPI_P0_RX_MAXLEN_REG reset 0x5EE — CPPI Port 0 Receive Frame Max Length
  [13:0] RX_MAXLEN — RX Maximum Frame Length. This field determines the maximum length of a received frame. The reset value is 1518 (dec). Frames with byte counts greater than the value in CPSW_P0_RX_MAXLEN_REG are long frames. Long frames with no errors are oversized frames. Long frames with CRC, code, or alignment error are jabber frames. The maximum value is 9604 (including VLAN) when fifo_blk_size = 4. When fifo_blk_size = 1 the maximum value is 2024 (including VLAN).
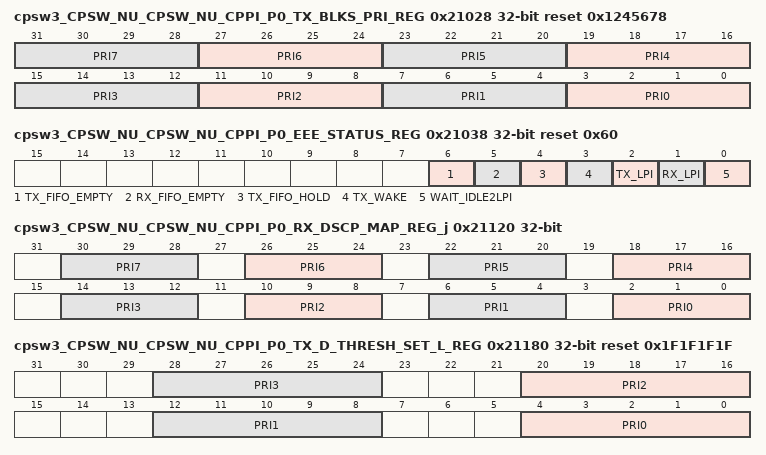
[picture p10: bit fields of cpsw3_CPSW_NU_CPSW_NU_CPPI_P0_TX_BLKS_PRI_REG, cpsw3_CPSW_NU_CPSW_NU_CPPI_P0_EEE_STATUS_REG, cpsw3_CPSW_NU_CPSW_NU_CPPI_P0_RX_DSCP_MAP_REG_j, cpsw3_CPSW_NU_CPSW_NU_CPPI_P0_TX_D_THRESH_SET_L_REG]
0x21028 cpsw3_CPSW_NU_CPSW_NU_CPPI_P0_TX_BLKS_PRI_REG reset 0x1245678 — CPPI Port 0 Transmit Block Sub Per Priority
  [4n+3:4n] PRI{n} (n=0..7) — Number of transmit 1kB blocks (defined in TX_MAX_BLKS field of CPSW_PN_MAX_BLKS_REG_k) from TX port buffer to not use for priority {n} frames (value 0 means use all).
0x21030 cpsw3_CPSW_NU_CPSW_NU_CPPI_P0_IDLE2LPI_REG — Port 0 EEE Idle to LPI counter
  [23:0] COUNT — Port 0 EEE Idle to LPI counter load value
0x21034 cpsw3_CPSW_NU_CPSW_NU_CPPI_P0_LPI2WAKE_REG — Port 0 EEE LPI to wake counter
  [23:0] COUNT — Port 0 EEE LPI to wake counter load value
0x21038 cpsw3_CPSW_NU_CPSW_NU_CPPI_P0_EEE_STATUS_REG ro reset 0x60 — Port 0 EEE status
  [6] TX_FIFO_EMPTY — CPPI port 0 transmit FIFO (switch egress) is empty - contains no packets
  [5] RX_FIFO_EMPTY — CPPI port 0 receive FIFO (switch ingress) is empty - contains no packets
  [4] TX_FIFO_HOLD — CPPI port 0 transmit FIFO hold - asserted in the LPI state and during the LPI2WAKE count time
  [3] TX_WAKE — CPPI port 0 transmit wakeup - asserted in the transmit LPI2WAKE count time
  [2] TX_LPI — CPPI port 0 transmit LPI state - asserted when the port 0 transmit is in the LPI state
  [1] RX_LPI — CPPI port 0 receive LPI state - asserted when the port 0 receive is in the LPI state
  [0] WAIT_IDLE2LPI — CPPI port 0 wait idle to LPI - asserted when port 0 is counting the IDLE2LPI time
0x21050 cpsw3_CPSW_NU_CPSW_NU_CPPI_P0_FIFO_STATUS_REG ro — Port 0 FIFO Status
  [7:0] TX_PRI_ACTIVE — Port 0 Transmit FIFO Priority Active. Each bit indicates whether the corresponding FIFO priority has one or more queued packets on it or not. Note: For N=2 this field is always zero (there is no transmit FIFO).
0x21120 cpsw3_CPSW_NU_CPSW_NU_CPPI_P0_RX_DSCP_MAP_REG_j — CPPI Port 0 Receive IPV4/IPV6 DSCP Map N
  [4n+2:4n] PRI{n} (n=0..7) — A DSCP IPV4/V6 packet TOS of N*8+{n} is mapped to this received priority
0x21140 cpsw3_CPSW_NU_CPSW_NU_CPPI_P0_PRI_CIR_REG_j — CPPI Port 0 Rx Priority P Committed Information Rate
  [27:0] PRI_CIR — Priority N Committed Information Rate Count Value
0x21160 cpsw3_CPSW_NU_CPSW_NU_CPPI_P0_PRI_EIR_REG_j — CPPI Port 0 Rx Priority P Excess Information Rate
  [27:0] PRI_EIR — Priority N EIR
0x21180 cpsw3_CPSW_NU_CPSW_NU_CPPI_P0_TX_D_THRESH_SET_L_REG reset 0x1F1F1F1F — CPPI Port 0 Tx PFC Destination Threshold Set Low
  [8n+4:8n] PRI{n} (n=0..3) — Port Priority Based Flow Control Threshold Set Value for Priority {n}
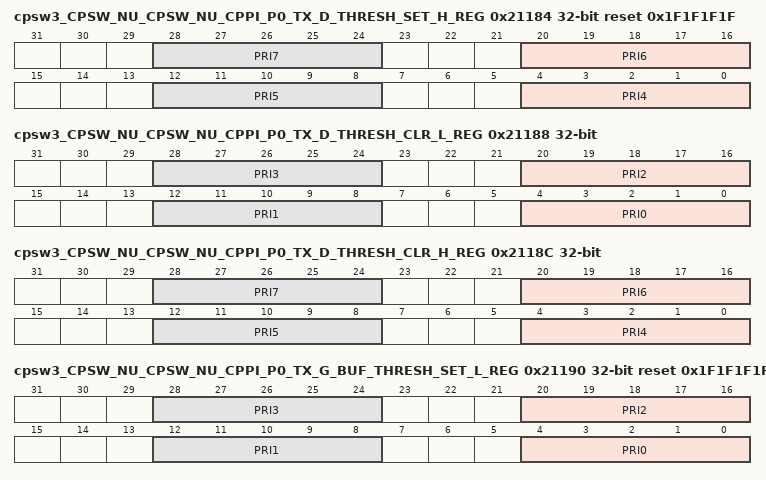
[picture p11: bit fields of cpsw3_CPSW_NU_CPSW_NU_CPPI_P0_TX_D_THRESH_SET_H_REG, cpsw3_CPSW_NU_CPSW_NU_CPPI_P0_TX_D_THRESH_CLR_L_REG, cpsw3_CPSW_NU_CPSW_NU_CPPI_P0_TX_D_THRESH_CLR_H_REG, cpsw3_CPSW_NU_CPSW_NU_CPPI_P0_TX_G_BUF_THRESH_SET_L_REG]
0x21184 cpsw3_CPSW_NU_CPSW_NU_CPPI_P0_TX_D_THRESH_SET_H_REG reset 0x1F1F1F1F — CPPI Port 0 Tx PFC Destination Threshold Set High
  [8n-28:8n-32] PRI{n} (n=4..7) — Port Priority Based Flow Control Threshold Set Value for Priority {n}
0x21188 cpsw3_CPSW_NU_CPSW_NU_CPPI_P0_TX_D_THRESH_CLR_L_REG — CPPI Port 0 Tx PFC Destination Threshold Clr Low
  [8n+4:8n] PRI{n} (n=0..3) — Port Priority Based Flow Control Threshold Clear Value for Priority {n}
0x2118C cpsw3_CPSW_NU_CPSW_NU_CPPI_P0_TX_D_THRESH_CLR_H_REG — CPPI Port 0 Tx PFC Destination Threshold Clr High
  [8n-28:8n-32] PRI{n} (n=4..7) — Port Priority Based Flow Control Threshold Clear Value for Priority {n}
0x21190 cpsw3_CPSW_NU_CPSW_NU_CPPI_P0_TX_G_BUF_THRESH_SET_L_REG reset 0x1F1F1F1F — CPPI Port 0 Tx PFC Global Buffer Threshold Set Low
  fields as cpsw3_CPSW_NU_CPSW_NU_CPPI_P0_TX_D_THRESH_SET_L_REG
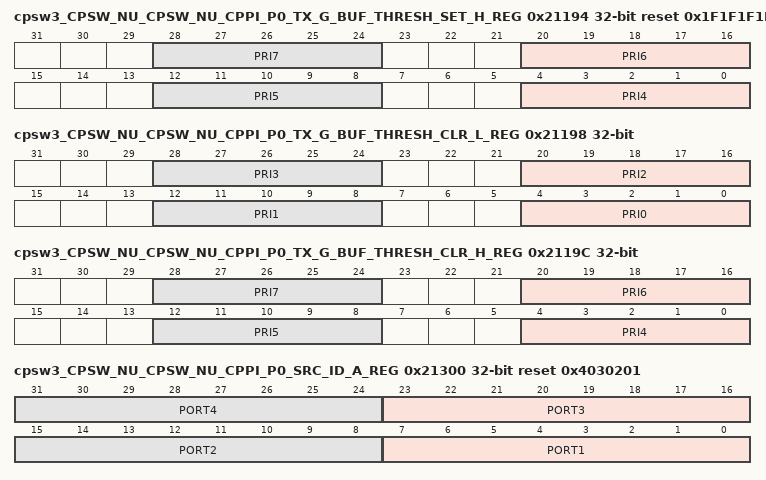
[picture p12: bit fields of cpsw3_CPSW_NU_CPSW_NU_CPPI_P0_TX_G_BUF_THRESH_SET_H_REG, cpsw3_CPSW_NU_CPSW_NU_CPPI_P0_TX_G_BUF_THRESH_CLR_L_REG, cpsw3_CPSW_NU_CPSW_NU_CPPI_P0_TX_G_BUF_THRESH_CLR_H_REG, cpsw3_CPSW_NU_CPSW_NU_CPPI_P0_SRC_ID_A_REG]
0x21194 cpsw3_CPSW_NU_CPSW_NU_CPPI_P0_TX_G_BUF_THRESH_SET_H_REG reset 0x1F1F1F1F — CPPI Port 0 Tx PFC Global Buffer Threshold Set High
  fields as cpsw3_CPSW_NU_CPSW_NU_CPPI_P0_TX_D_THRESH_SET_H_REG
0x21198 cpsw3_CPSW_NU_CPSW_NU_CPPI_P0_TX_G_BUF_THRESH_CLR_L_REG — CPPI Port 0 Tx PFC Global Buffer Threshold Clr Low
  fields as cpsw3_CPSW_NU_CPSW_NU_CPPI_P0_TX_D_THRESH_CLR_L_REG
0x2119C cpsw3_CPSW_NU_CPSW_NU_CPPI_P0_TX_G_BUF_THRESH_CLR_H_REG — CPPI Port 0 Tx PFC Global Buffer Threshold Clr High
  fields as cpsw3_CPSW_NU_CPSW_NU_CPPI_P0_TX_D_THRESH_CLR_H_REG
0x21300 cpsw3_CPSW_NU_CPSW_NU_CPPI_P0_SRC_ID_A_REG reset 0x4030201 — CPPI Port 0 CPPI Source ID A
  [8n-1:8n-8] PORT{n} (n=1..4) — Port {n} CPPI Info Word0 Source ID Value. This value is contained in the CPPI Info Word 0 SRC_ID field for packets received on port {n}.
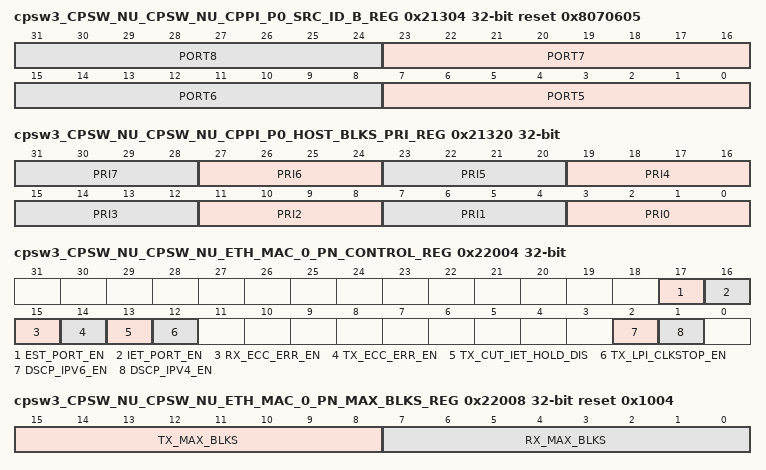
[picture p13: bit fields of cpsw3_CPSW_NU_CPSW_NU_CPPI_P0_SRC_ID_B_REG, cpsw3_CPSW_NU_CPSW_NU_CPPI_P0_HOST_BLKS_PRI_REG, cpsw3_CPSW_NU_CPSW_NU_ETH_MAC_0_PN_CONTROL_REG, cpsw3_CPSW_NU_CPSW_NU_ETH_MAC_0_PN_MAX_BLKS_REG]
0x21304 cpsw3_CPSW_NU_CPSW_NU_CPPI_P0_SRC_ID_B_REG reset 0x8070605 — CPPI Port 0 CPPI Source ID B
  [8n-33:8n-40] PORT{n} (n=5..8) — Port {n} CPPI Info Word0 Source ID Value. This value is contained in the CPPI Info Word 0 SRC_ID field for packets received on port {n}.
0x21320 cpsw3_CPSW_NU_CPSW_NU_CPPI_P0_HOST_BLKS_PRI_REG — CPPI Port 0 Host Blocks Priority
  [4n+3:4n] PRI{n} (n=0..7) — Priority {n} Host Blocks
0x22000 cpsw3_CPSW_NU_CPSW_NU_ETH_MAC_0 access not given reset not defined
0x22000 cpsw3_CPSW_NU_CPSW_NU_ETH_MAC_0_PN_RESERVED_REG ro — Reserved
0x22004 cpsw3_CPSW_NU_CPSW_NU_ETH_MAC_0_PN_CONTROL_REG — Enet Port N Control
  [17] EST_PORT_EN — EST Port Enable
  [16] IET_PORT_EN — IET Port Enable
  [15] RX_ECC_ERR_EN — Port 0 Receive ECC Error Enable
  [14] TX_ECC_ERR_EN — Port 0 Transmit ECC Error Enable
  [13] TX_CUT_IET_HOLD_DIS — Cut-Thru IET Prempt Hold Disable
  [12] TX_LPI_CLKSTOP_EN — Transmit LPI clockstop enable
  [2] DSCP_IPV6_EN — IPv6 DSCP enable
  [1] DSCP_IPV4_EN — IPv4 DSCP enable
0x22008 cpsw3_CPSW_NU_CPSW_NU_ETH_MAC_0_PN_MAX_BLKS_REG reset 0x1004 — Enet Port N FIFO Max Blocks
  [15:8] TX_MAX_BLKS — Transmit FIFO maximum blocks
  [7:0] RX_MAX_BLKS — Receive FIFO maximum blocks
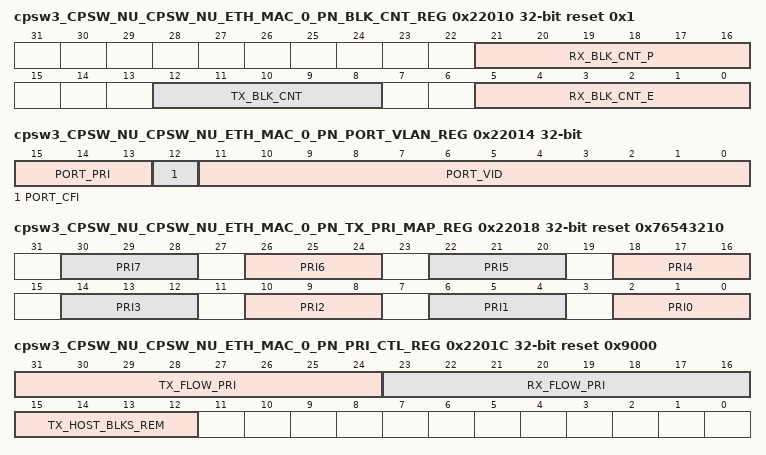
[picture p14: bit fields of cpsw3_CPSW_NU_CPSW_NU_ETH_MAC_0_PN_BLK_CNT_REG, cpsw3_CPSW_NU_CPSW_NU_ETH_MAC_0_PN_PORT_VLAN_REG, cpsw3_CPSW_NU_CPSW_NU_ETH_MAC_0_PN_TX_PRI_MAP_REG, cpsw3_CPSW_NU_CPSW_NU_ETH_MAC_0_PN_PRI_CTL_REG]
0x22010 cpsw3_CPSW_NU_CPSW_NU_ETH_MAC_0_PN_BLK_CNT_REG ro reset 0x1 — Enet Port N FIFO Block Usage Count
  [21:16] RX_BLK_CNT_P — Receive Prempt Queue Block Count Usage
  [12:8] TX_BLK_CNT — Transmit Block Count Usage
  [5:0] RX_BLK_CNT_E — Receive Block Count Usage
0x22014 cpsw3_CPSW_NU_CPSW_NU_ETH_MAC_0_PN_PORT_VLAN_REG — Enet Port N VLAN
  fields as cpsw3_CPSW_NU_CPSW_NU_CPPI_P0_PORT_VLAN_REG
0x22018 cpsw3_CPSW_NU_CPSW_NU_ETH_MAC_0_PN_TX_PRI_MAP_REG reset 0x76543210 — Enet Port N Tx Header Pri to Switch Pri Mapping
  [4n+2:4n] PRI{n} (n=0..7) — Priority {n}
0x2201C cpsw3_CPSW_NU_CPSW_NU_ETH_MAC_0_PN_PRI_CTL_REG reset 0x9000 — Enet Port N Priority Control
  [31:24] TX_FLOW_PRI — Transmit Priority Based Flow Control Enable (per priority)
  [23:16] RX_FLOW_PRI — Receive Priority Based Flow Control Enable (per priority)
  [15:12] TX_HOST_BLKS_REM — Transmit FIFO Blocks that must be free before a non rate-limited CPPI Port 0 receive thread can begin sending a packet
0x22020 cpsw3_CPSW_NU_CPSW_NU_ETH_MAC_0_PN_RX_PRI_MAP_REG reset 0x76543210 — Enet Port N RX Pkt Pri to Header Pri Map
  [4n+2:4n] PRI{n} (n=0..7) — Priority {n}
0x22024 cpsw3_CPSW_NU_CPSW_NU_ETH_MAC_0_PN_RX_MAXLEN_REG reset 0x5EE — Enet Port N Receive Frame Max Length
  [13:0] RX_MAXLEN — Rx Maximum Frame Length
0x22028 cpsw3_CPSW_NU_CPSW_NU_ETH_MAC_0_PN_TX_BLKS_PRI_REG reset 0x1245678 — Enet Port N Transmit Block Sub Per Priority
  [4n+3:4n] PRI{n} (n=0..7) — Priority {n} Port Transmit Blocks
0x22030 cpsw3_CPSW_NU_CPSW_NU_ETH_MAC_0_PN_IDLE2LPI_REG — Enet Port N EEE Idle to LPI counter
  [23:0] COUNT — EEE Idle to LPI counter load value
0x22034 cpsw3_CPSW_NU_CPSW_NU_ETH_MAC_0_PN_LPI2WAKE_REG — Enet Port N EEE LPI to wake counter
  [23:0] COUNT — EEE LPI to wake counter load value
0x22038 cpsw3_CPSW_NU_CPSW_NU_ETH_MAC_0_PN_EEE_STATUS_REG ro reset 0x62 — Enet Port N EEE status
  [6] TX_FIFO_EMPTY — Transmit FIFO (switch egress) is empty - contains no packets
  [5] RX_FIFO_EMPTY — Receive FIFO (switch ingress) is empty - contains no packets
  [4] TX_FIFO_HOLD — Transmit FIFO hold - asserted in the LPI state and during the LPI2WAKE count time
  [3] TX_WAKE — Transmit wakeup - asserted in the transmit LPI2WAKE count time
  [2] TX_LPI — Transmit LPI state - asserted when the port 0 transmit is in the LPI state
  [1] RX_LPI — Receive LPI state - asserted when the port 0 receive is in the LPI state
  [0] WAIT_IDLE2LPI — CPPI port 0 wait idle to LPI - asserted when port 0 is counting the IDLE2LPI time
0x22040 cpsw3_CPSW_NU_CPSW_NU_ETH_MAC_0_PN_IET_CONTROL_REG reset 0x8 — Enet Port N IET Control
  [23:16] MAC_PREMPT — IET MAC Fragment Size
  [10:8] MAC_ADDFRAGSIZE — IET MAC Fragment Size
  [3] MAC_LINKFAIL — IET MAC LINK Fail Reset
  [2] MAC_DISABLEVERIFY — IET MAC Disable Verify
  [1] MAC_HOLD — IET MAC HOLD
  [0] MAC_PENABLE — IET MAC Penable
0x22044 cpsw3_CPSW_NU_CPSW_NU_ETH_MAC_0_PN_IET_STATUS_REG ro — Enet Port N IET Status
  [3] MAC_VERIFY_ERR — IET MAC VERIFY ERROR
  [2] MAC_RESPOND_ERR — IET MAC RESPONSE ERROR
  [1] MAC_VERIFY_FAIL — IET MAC VERIFY FAIL
  [0] MAC_VERIFIED — IET MAC VERIFIED
